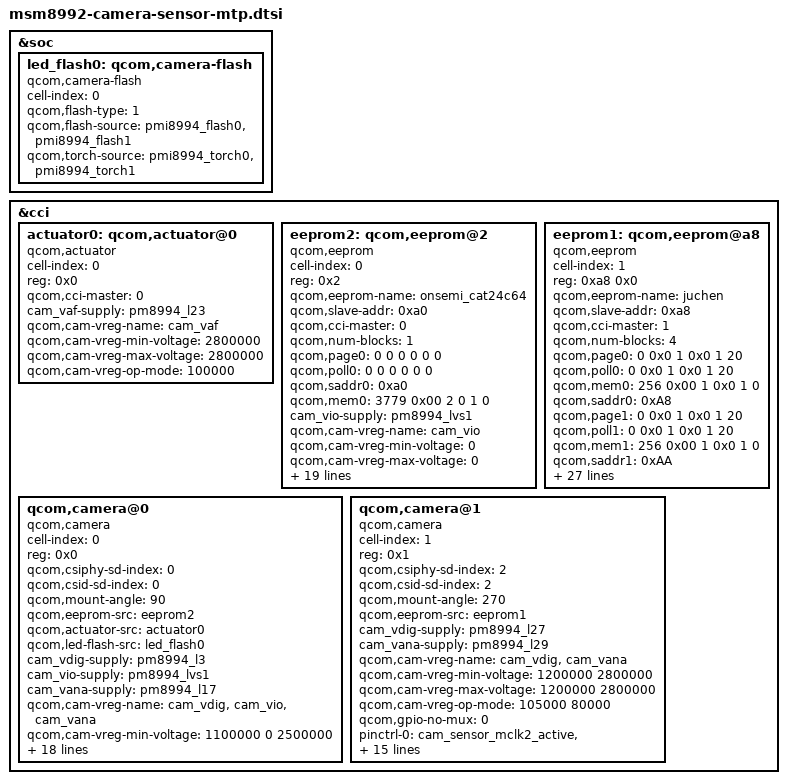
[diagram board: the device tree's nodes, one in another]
/*
 * Copyright (c) 2014-2015, The Linux Foundation. All rights reserved.
 *
 * This program is free software; you can redistribute it and/or modify
 * it under the terms of the GNU General Public License version 2 and
 * only version 2 as published by the Free Software Foundation.
 *
 * This program is distributed in the hope that it will be useful,
 * but WITHOUT ANY WARRANTY; without even the implied warranty of
 * MERCHANTABILITY or FITNESS FOR A PARTICULAR PURPOSE.  See the
 * GNU General Public License for more details.
 */

&soc {
	led_flash0: qcom,camera-flash {
		cell-index = <0>;
		compatible = "qcom,camera-flash";
		qcom,flash-type = <1>;
		qcom,flash-source = <&pmi8994_flash0 &pmi8994_flash1>;
		qcom,torch-source = <&pmi8994_torch0 &pmi8994_torch1>;
	};
};

&cci {
	actuator0: qcom,actuator@0 {
		cell-index = <0>;
		reg = <0x0>;
		compatible = "qcom,actuator";
		qcom,cci-master = <0>;
		cam_vaf-supply = <&pm8994_l23>;
		qcom,cam-vreg-name = "cam_vaf";
		qcom,cam-vreg-min-voltage = <2800000>;
		qcom,cam-vreg-max-voltage = <2800000>;
		qcom,cam-vreg-op-mode = <100000>;
	};

	eeprom2: qcom,eeprom@2 {
		cell-index = <0>;
		reg = <0x2>;
		qcom,eeprom-name = "onsemi_cat24c64";
		compatible = "qcom,eeprom";
		qcom,slave-addr = <0xa0>;
		qcom,cci-master = <0>;
		qcom,num-blocks = <1>;
		qcom,page0 = <0 0 0 0 0 0>;
		qcom,poll0 = <0 0 0 0 0 0>;
		qcom,saddr0 = <0xa0>;
		qcom,mem0 = <3779 0x00 2 0 1 0>;

		cam_vio-supply = <&pm8994_lvs1>;
		qcom,cam-vreg-name = "cam_vio";
		qcom,cam-vreg-min-voltage = <0>;
		qcom,cam-vreg-max-voltage = <0>;
		qcom,cam-vreg-op-mode = <0>;

		qcom,gpio-no-mux = <0>;
		pinctrl-names = "cam_default", "cam_suspend";
		pinctrl-0 = <&cam_sensor_mclk0_active &cam_sensor_rear_active>;
		pinctrl-1 = <&cam_sensor_mclk0_suspend &cam_sensor_rear_suspend>;
		gpios = <&msm_gpio 13 0>,
			<&msm_gpio 92 0>;
		qcom,gpio-reset = <1>;
		qcom,gpio-req-tbl-num = <0 1>;
		qcom,gpio-req-tbl-flags = <1 0>;
		qcom,gpio-req-tbl-label = "CAMIF_MCLK0",
					  "CAM_RESET0";

         	qcom,i2c-freq-mode = <1>;
		qcom,cam-power-seq-type = "sensor_vreg";
		qcom,cam-power-seq-val = "cam_vio";
		qcom,cam-power-seq-cfg-val = <1>;
		qcom,cam-power-seq-delay = <1>;
		status = "ok";
		clocks = <&clock_mmss clk_mclk0_clk_src>,
				<&clock_mmss clk_camss_mclk0_clk>;
		clock-names = "cam_src_clk", "cam_clk";
	};

	eeprom1: qcom,eeprom@a8 {
		cell-index = <1>;
		reg = <0xa8 0x0>;
		qcom,eeprom-name = "juchen";
		compatible = "qcom,eeprom";
		qcom,slave-addr = <0xa8>;
		qcom,cci-master = <1>;
		qcom,num-blocks = <4>;

		qcom,page0 = <0 0x0 1 0x0 1 20>;
		qcom,poll0 = <0 0x0 1 0x0 1 20>;
		qcom,mem0 = <256 0x00 1 0x0 1 0>;
		qcom,saddr0 = <0xA8>;

		qcom,page1 = <0 0x0 1 0x0 1 20>;
		qcom,poll1 = <0 0x0 1 0x0 1 20>;
		qcom,mem1 = <256 0x00 1 0x0 1 0>;
		qcom,saddr1 = <0xAA>;


		qcom,page2 = <0 0x0 1 0x0 1 20>;
		qcom,poll2 = <0 0x0 1 0x0 1 20>;
		qcom,mem2 = <256 0x00 1 0x0 1 0>;
		qcom,saddr2 = <0xAC>;


		qcom,page3 = <0 0x0 1 0x0 1 20>;
		qcom,poll3 = <0 0x0 1 0x0 1 20>;
		qcom,mem3 = <256 0x00 1 0x0 1 0>;
		qcom,saddr3 = <0xAE>;

		qcom,cam-vreg-name = "cam_vdig","cam_vana";
		qcom,cam-vreg-min-voltage = <1200000 2800000>;
		qcom,cam-vreg-max-voltage = <1200000 2800000>;
		qcom,cam-vreg-op-mode = <105000 80000>;

		qcom,gpio-no-mux = <0>;
		pinctrl-names = "cam_default", "cam_suspend";
		pinctrl-0 = <&cam_sensor_mclk2_active &cam_sensor_front_active>;
		pinctrl-1 = <&cam_sensor_mclk2_suspend &cam_sensor_front_suspend>;
		gpios = <&msm_gpio 93 0>; //"CAM_VIO"
	
		qcom,gpio-vio = <0>;
		qcom,gpio-req-tbl-num = <0 >;
		qcom,gpio-req-tbl-flags = <0 >;
		qcom,gpio-req-tbl-label = "CAM_VIO";
         qcom,i2c-freq-mode = <1>;
		qcom,cam-power-seq-type = "sensor_gpio";
		qcom,cam-power-seq-val = "sensor_gpio_vio";
		qcom,cam-power-seq-cfg-val = <1>;
		qcom,cam-power-seq-delay = <2>;
	};

	qcom,camera@0 {
		cell-index = <0>;
		compatible = "qcom,camera";
		reg = <0x0>;
		qcom,csiphy-sd-index = <0>;
		qcom,csid-sd-index = <0>;
		qcom,mount-angle = <90>;
		qcom,eeprom-src = <&eeprom2>;
		qcom,actuator-src = <&actuator0>;
//		qcom,ois-src = <&ois0>;
		qcom,led-flash-src = <&led_flash0>;
		cam_vdig-supply = <&pm8994_l3>;
		cam_vio-supply = <&pm8994_lvs1>;
		cam_vana-supply = <&pm8994_l17>;
		qcom,cam-vreg-name = "cam_vdig", "cam_vio", "cam_vana";
		qcom,cam-vreg-min-voltage = <1100000 0 2500000>;
		qcom,cam-vreg-max-voltage = <1100000 0 2500000>;
		qcom,cam-vreg-op-mode = <105000 0 80000>;
		qcom,gpio-no-mux = <0>;
		pinctrl-names = "cam_default", "cam_suspend";
		pinctrl-0 = <&cam_sensor_mclk0_active &cam_sensor_rear_active>;
		pinctrl-1 = <&cam_sensor_mclk0_suspend &cam_sensor_rear_suspend>;
		gpios = <&msm_gpio 13 0>,
			<&msm_gpio 92 0>;
		qcom,gpio-reset = <1>;
		qcom,gpio-req-tbl-num = <0 1>;
		qcom,gpio-req-tbl-flags = <1 0>;
		qcom,gpio-req-tbl-label = "CAMIF_MCLK0",
					  "CAM_RESET0";
		qcom,sensor-position = <0>;
		qcom,sensor-mode = <0>;
		qcom,cci-master = <0>;
		status = "ok";
		clocks = <&clock_mmss clk_mclk0_clk_src>,
				<&clock_mmss clk_camss_mclk0_clk>;
		clock-names = "cam_src_clk", "cam_clk";
	};

	qcom,camera@1 {
		cell-index = <1>;
		
		compatible = "qcom,camera";
		reg = <0x1>;
		qcom,csiphy-sd-index = <2>;
		qcom,csid-sd-index = <2>;
		qcom,mount-angle = <270>;
		qcom,eeprom-src = <&eeprom1>;
		cam_vdig-supply = <&pm8994_l27>;
		//cam_vio-supply = <&pm8994_lvs1>;
		cam_vana-supply = <&pm8994_l29>;
		qcom,cam-vreg-name = "cam_vdig","cam_vana";
		qcom,cam-vreg-min-voltage = <1200000 2800000>;
		qcom,cam-vreg-max-voltage = <1200000 2800000>;
		qcom,cam-vreg-op-mode = <105000 80000>;
		qcom,gpio-no-mux = <0>;
		pinctrl-names = "cam_default", "cam_suspend";
		pinctrl-0 = <&cam_sensor_mclk2_active &cam_sensor_front_active>;
		pinctrl-1 = <&cam_sensor_mclk2_suspend &cam_sensor_front_suspend>;
		gpios = <&msm_gpio 15 0>,
			<&msm_gpio 94 0>,
			<&msm_gpio 93 0>; //"CAM_VIO"
		qcom,gpio-reset = <1>;
		qcom,gpio-vio = <2>;
		qcom,gpio-req-tbl-num = <0 1 2>;
		qcom,gpio-req-tbl-flags = <1 0 0>;
		qcom,gpio-req-tbl-label = "CAMIF_MCLK2",
					  "CAM_RESET2",
					  "CAM_VIO";
		qcom,sensor-position = <1>;
		qcom,sensor-mode = <1>;
		qcom,cci-master = <1>;
		status = "ok";
		clocks = <&clock_mmss clk_mclk2_clk_src>,
			<&clock_mmss clk_camss_mclk2_clk>;
		clock-names = "cam_src_clk", "cam_clk";
	};

};
